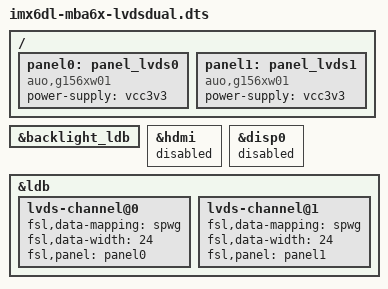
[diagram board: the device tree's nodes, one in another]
/*
 * Copyright 2014 Markus Niebel, TQ Systems GmbH
 *
 * The code contained herein is licensed under the GNU General Public
 * License. You may obtain a copy of the GNU General Public License
 * Version 2 or later at the following locations:
 *
 * http://www.opensource.org/licenses/gpl-license.html
 * http://www.gnu.org/copyleft/gpl.html
 */

#include "imx6dl-mba6x.dts"

/ {
	panel0: panel_lvds0 {
		compatible = "auo,g156xw01";
		power-supply = <&vcc3v3>;
	};
	panel1: panel_lvds1 {
		compatible = "auo,g156xw01";
		power-supply = <&vcc3v3>;
	};
};

&backlight_ldb {
	status = "okay";
};

&hdmi {
	status = "disabled";
};

&disp0 {
	status = "disabled";
};

&ldb {
	status = "okay";

	lvds-channel@0 {
		fsl,data-mapping = "spwg";
		fsl,data-width = <24>;
		fsl,panel = <&panel0>;
		status = "okay";
	};

	lvds-channel@1 {
		fsl,data-mapping = "spwg";
		fsl,data-width = <24>;
		fsl,panel = <&panel1>;
		status = "okay";
	};
};
